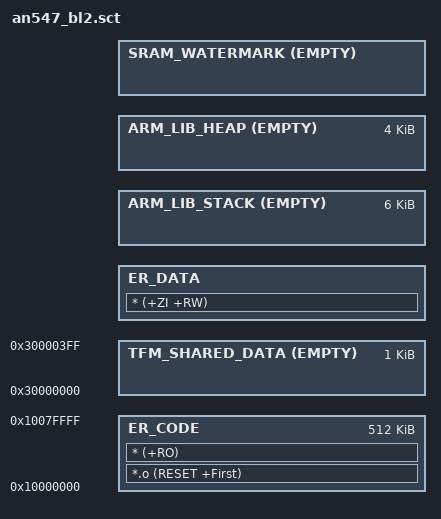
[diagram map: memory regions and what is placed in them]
/*
 * Copyright (c) 2021-2022 Arm Limited. All rights reserved.
 *
 * Licensed under the Apache License, Version 2.0 (the "License");
 * you may not use this file except in compliance with the License.
 * You may obtain a copy of the License at
 *
 *     http://www.apache.org/licenses/LICENSE-2.0
 *
 * Unless required by applicable law or agreed to in writing, software
 * distributed under the License is distributed on an "AS IS" BASIS,
 * WITHOUT WARRANTIES OR CONDITIONS OF ANY KIND, either express or implied.
 * See the License for the specific language governing permissions and
 * limitations under the License.
 */

LR_CODE (0x10000000) {
    ER_CODE (0x10000000) ((0x00080000)) {
        *.o (RESET +First)
        * (+RO)
    }

    TFM_SHARED_DATA (0x30000000) ALIGN 32 EMPTY (0x400) {
    }

    ER_DATA +0 {
        * (+ZI +RW)
    }


    ARM_LIB_STACK +0 ALIGN 32 EMPTY (0x0001800) {
    }

    ARM_LIB_HEAP +0 ALIGN 8 EMPTY (0x0001000) {
    }




    SRAM_WATERMARK +0 EMPTY 0x0 {
    }




    ScatterAssert(ImageLimit(SRAM_WATERMARK) <= ((0x30000000)) + (((0x00020000) * (0x4))))
}
